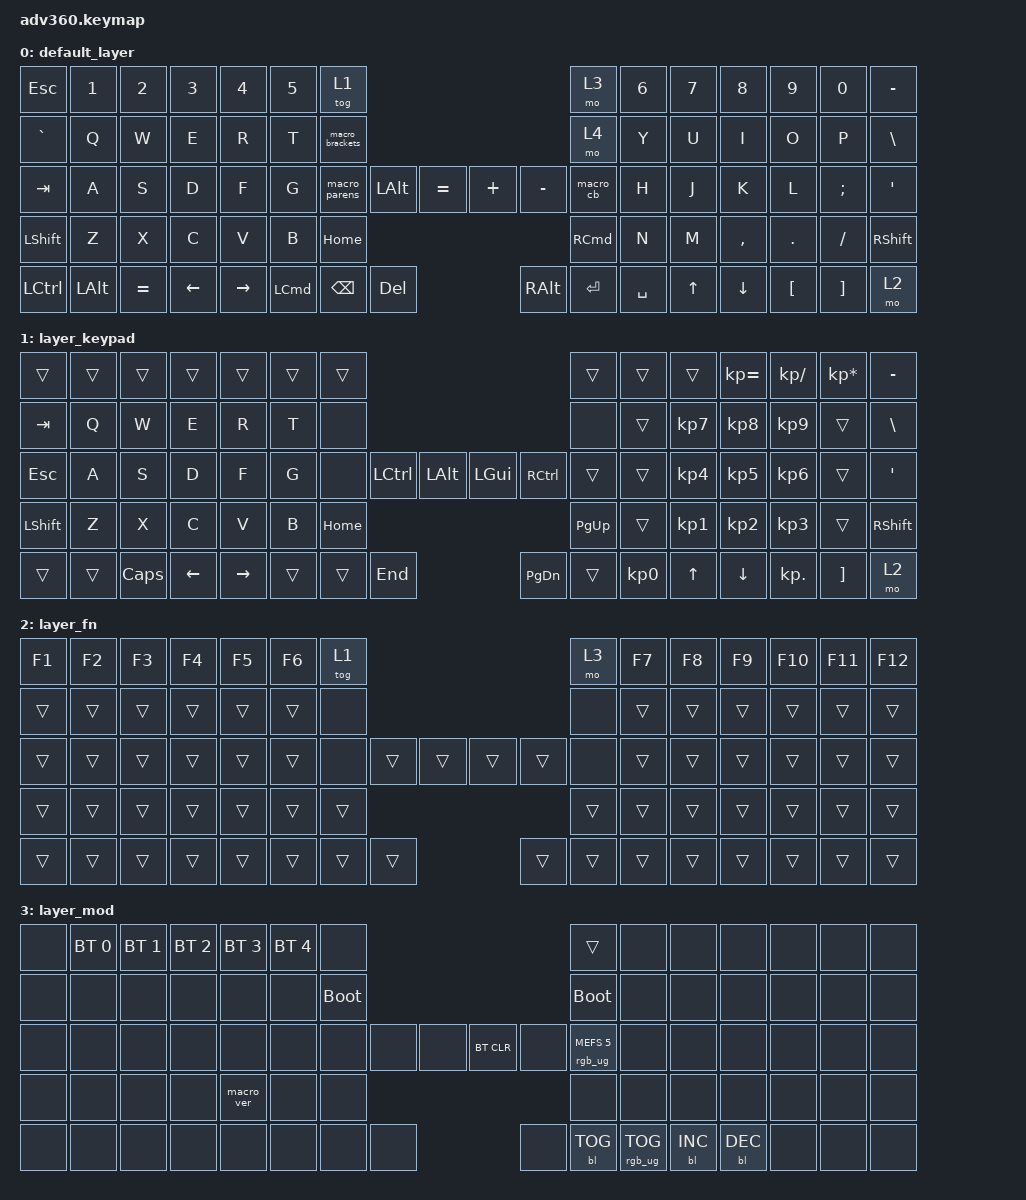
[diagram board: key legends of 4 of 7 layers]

/*
 * Copyright (c) 2020 The ZMK Contributors
 *
 * SPDX-License-Identifier: MIT
 */


/* THIS FILE WAS GENERATED!
 *
 * This file was generated automatically. You may or may not want to
 * edit it directly.
 */

#include <behaviors.dtsi>
#include <dt-bindings/zmk/keys.h>
#include <dt-bindings/zmk/bt.h>
#include <dt-bindings/zmk/rgb.h>
#include <dt-bindings/zmk/backlight.h>
#include "adv360keys.h"

#define COMBO(NAME, BINDINGS, KEYPOS) \
  combo_##NAME { \
    timeout-ms = <20>; \
    bindings = <BINDINGS>; \
    key-positions = <KEYPOS>; \
    layers = <0>; \
  };

&sk {
  release-after-ms = <STICKY_KEY_TIMEOUT>;
};

#define HYP(key) LS(LC(LA(LG(key))))
#define HYPER    LS(LC(LA(LGUI)))

#define MACLOCK  LG(LC(Q))

#define BROWSER_SEARCH LG(F)
#define BROWSER_NEWTAB LG(T)
#define BROWSER_CLOSETTAB LG(W)
#define BROWSER_NEXTTAB LG(LA(RIGHT))
#define BROWSER_PREVTAB LG(LA(LEFT))

&mt {
    tapping-term-ms = <210>;
    flavor = "tap-preferred";
};

&lt {
    quick_tap_ms = <200>;
};

/ {
    behaviors {
      #include "macros.dtsi"
      #include "version.dtsi"
      #ifndef VERSION_MACRO
      macro_ver: macro_ver {
        compatible = "zmk,behavior-macro";
        label = "macro_version";
        #binding-cells = <0>;
        bindings = <&kp RET>;
      };
      #endif
    combos {
      compatible = "zmk,combos";
      /* Brackets */
      COMBO(left_bracket, &kp LBKT, 0 10)
      COMBO(right_bracket, &kp RBKT, 7 17)
      COMBO(left_parenthesis, &kp LPAR, 1 11)
      COMBO(right_parenthesis, &kp RPAR, 6 16)
      COMBO(left_brace, &kp LBRC, 2 12)
      COMBO(right_brace, &kp RBRC, 5 15)
      /* Text */
      COMBO(redo, &kp LG(LS(Z)), 2 3)
      COMBO(undo, &kp LG(Z), 12 13)
      COMBO(redow, &kp LC(Y), 2 3)
      COMBO(undow, &kp LC(Z), 12 13)
      COMBO(caps_word, &caps_word, 31 32)
      COMBO(key_repeat_l, &key_repeat, 23 24)
      COMBO(key_repeat_r, &key_repeat, 25 26)
      COMBO(alfred, &kp LG(SPACE), 21 23)
      COMBO(clpbrd, &kp LG(LC(LA(LS(Z)))), 21 22 23)
      COMBO(esc, &kp ESC, 23 30)
    };

    // Sticky key on tap, normal key on hold
    // Useful for modifier-clicking without the modifier remaining active
    nk: not_so_sticky_key {
      compatible = "zmk,behavior-hold-tap";
      label = "NOT_SO_STICKY_KEY";
      #binding-cells = <2>;
      tapping_term_ms = <200>;
      flavor = "tap-preferred";
      bindings = <&kp>, <&sk>;
    };

    hm: homerow_mods {
        compatible = "zmk,behavior-hold-tap";
        label = "HOMEROW_MODS";
        #binding-cells = <2>;
        tapping-term-ms = <200>;
        quick_tap_ms = <175>;
        flavor = "tap-preferred";
        bindings = <&kp>, <&kp>;
    };
    gpipe: grave_pipe {
      compatible = "zmk,behavior-mod-morph";
      label = "grave_pipe";
      #binding-cells = <0>;
      bindings = <&kp GRAVE>, <&kp PIPE>;
      mods = <(MOD_LGUI|MOD_LSFT|MOD_RGUI|MOD_RSFT)>;
    };
  ppipe: pipe_pipe {
    compatible = "zmk,behavior-mod-morph";
    label = "pipe_pipe";
    #binding-cells = <0>;
    bindings = <&kp PIPE>, <&kp PIPE>;
    mods = <(MOD_LGUI|MOD_LSFT|MOD_RGUI|MOD_RSFT)>;
  };
  pkp_n1: plus_kp_n1 {
    compatible = "zmk,behavior-mod-morph";
    label = "plus_kp_n1";
    #binding-cells = <0>;
    bindings = <&kp PLUS>, <&kp KP_N1>;
    mods = <(MOD_LGUI|MOD_LSFT|MOD_RGUI|MOD_RSFT)>;
  };
  lkp_n2: left_bracket_kp_n2 {
    compatible = "zmk,behavior-mod-morph";
    label = "left_bracket_kp_n2";
    #binding-cells = <0>;
    bindings = <&kp LEFT_BRACKET>, <&kp KP_N2>;
    mods = <(MOD_LGUI|MOD_LSFT|MOD_RGUI|MOD_RSFT)>;
  };
  lkp_n3: left_brace_kp_n3 {
    compatible = "zmk,behavior-mod-morph";
    label = "left_brace_kp_n3";
    #binding-cells = <0>;
    bindings = <&kp LEFT_BRACE>, <&kp KP_N3>;
    mods = <(MOD_LGUI|MOD_LSFT|MOD_RGUI|MOD_RSFT)>;
  };
  lkp_n4: left_parenthesis_kp_n4 {
    compatible = "zmk,behavior-mod-morph";
    label = "left_parenthesis_kp_n4";
    #binding-cells = <0>;
    bindings = <&kp LEFT_PARENTHESIS>, <&kp KP_N4>;
    mods = <(MOD_LGUI|MOD_LSFT|MOD_RGUI|MOD_RSFT)>;
  };
  akp_n5: amps_kp_n5 {
    compatible = "zmk,behavior-mod-morph";
    label = "amps_kp_n5";
    #binding-cells = <0>;
    bindings = <&kp AMPS>, <&kp KP_N5>;
    mods = <(MOD_LGUI|MOD_LSFT|MOD_RGUI|MOD_RSFT)>;
  };
  ekp_n6: equal_kp_n6 {
    compatible = "zmk,behavior-mod-morph";
    label = "equal_kp_n6";
    #binding-cells = <0>;
    bindings = <&kp EQUAL>, <&kp KP_N6>;
    mods = <(MOD_LGUI|MOD_LSFT|MOD_RGUI|MOD_RSFT)>;
  };
  eekp_n6: kp_n6_equal {
    compatible = "zmk,behavior-mod-morph";
    label = "kp_n6_equal";
    #binding-cells = <0>;
    bindings = <&kp KP_N6>,  <&kp EQUAL>;
    mods = <(MOD_LGUI|MOD_LSFT|MOD_RGUI|MOD_RSFT)>;
  };

  rkp_n7: right_parenthesis_kp_n7 {
    compatible = "zmk,behavior-mod-morph";
    label = "right_parenthesis_kp_n7";
    #binding-cells = <0>;
    bindings = <&kp RIGHT_PARENTHESIS>, <&kp KP_N7>;
    mods = <(MOD_LGUI|MOD_LSFT|MOD_RGUI|MOD_RSFT)>;
  };
  rkp_n8: right_brace_kp_n8 {
    compatible = "zmk,behavior-mod-morph";
    label = "right_brace_kp_n8";
    #binding-cells = <0>;
    bindings = <&kp RIGHT_BRACE>, <&kp KP_N8>;
    mods = <(MOD_LGUI|MOD_LSFT|MOD_RGUI|MOD_RSFT)>;
  };
  rkp_n9: right_bracket_kp_n9 {
    compatible = "zmk,behavior-mod-morph";
    label = "right_bracket_kp_n9";
    #binding-cells = <0>;
    bindings = <&kp RIGHT_BRACKET>, <&kp KP_N9>;
    mods = <(MOD_LGUI|MOD_LSFT|MOD_RGUI|MOD_RSFT)>;
};
  skp_n0: star_kp_n0 {
    compatible = "zmk,behavior-mod-morph";
    label = "star_kp_n0";
    #binding-cells = <0>;
    bindings = <&kp STAR>, <&kp KP_N0>;
    mods = <(MOD_LGUI|MOD_LSFT|MOD_RGUI|MOD_RSFT)>;
  };
  eprcnt: excl_prcnt {
    compatible = "zmk,behavior-mod-morph";
    label = "excl_prcnt";
    #binding-cells = <0>;
    bindings = <&kp EXCL>, <&kp PRCNT>;
    mods = <(MOD_LGUI|MOD_LSFT|MOD_RGUI|MOD_RSFT)>;
  };

  dgrave: dllr_grave {
    compatible = "zmk,behavior-mod-morph";
    label = "dllr_grave";
    #binding-cells = <0>;
    bindings = <&kp DLLR>, <&kp GRAVE>;
    mods = <(MOD_LGUI|MOD_LSFT|MOD_RGUI|MOD_RSFT)>;
  };
  ggrave: grave_grave {
    compatible = "zmk,behavior-mod-morph";
    label = "grave_grave";
    #binding-cells = <0>;
    bindings = <&kp GRAVE>, <&kp GRAVE>;
    mods = <(MOD_LGUI|MOD_LSFT|MOD_RGUI|MOD_RSFT)>;
  };
  bhash: bslh_hash {
    compatible = "zmk,behavior-mod-morph";
    label = "bslh_hash";
    #binding-cells = <0>;
    bindings = <&kp BSLH>, <&kp HASH>;
    mods = <(MOD_LGUI|MOD_LSFT|MOD_RGUI|MOD_RSFT)>;
  };
  acaret: at_caret {
    compatible = "zmk,behavior-mod-morph";
    label = "at_caret";
    #binding-cells = <0>;
    bindings = <&kp AT>, <&kp CARET>;
    mods = <(MOD_LGUI|MOD_LSFT|MOD_RGUI|MOD_RSFT)>;
  };
};

keymap {
  compatible = "zmk,keymap";

/* Note that default_layer is 0, layer_keypad is 1, layer_fn is 2 */
    default_layer {
      bindings = <
        &kp ESC   &kp N1    &kp N2   &kp N3   &kp N4     &kp N5 &tog 1                                                           &mo 3     &kp N6 &kp N7 &kp N8    &kp N9   &kp N0   &kp MINUS
        &kp GRAVE &kp Q     &kp W    &kp E    &kp R      &kp T  &macro_brackets                                                  &mo 4     &kp Y  &kp U  &kp I     &kp O    &kp P    &kp BSLH
        &kp TAB   &kp A     &kp S    &kp D    &kp F      &kp G  &macro_parens   &kp LALT &kp EQUAL &kp PLUS  &kp MINUS           &macro_cb &kp H  &kp J  &kp K     &kp L    &kp SEMI &kp SQT
        &kp LSHFT &kp Z     &kp X    &kp C    &kp V      &kp B                            &kp HOME &kp RCMD                                &kp N  &kp M  &kp COMMA &kp DOT  &kp FSLH &kp RSHFT
        &kp LCTRL &kp LALT &kp EQUAL &kp LEFT &kp RIGHT                &kp LCMD &kp BSPC  &kp DEL  &kp RALT  &kp ENTER &kp SPACE                  &kp UP &kp DOWN  &kp LBKT &kp RBKT &mo 2
      >;
    };

    /* LAYER 1 */
    layer_keypad {
      bindings = <
        &trans   &trans    &trans   &trans   &trans     &trans  &trans                                                           &trans &trans &trans  &kp KP_EQUAL &kp KP_DIVIDE &kp KP_MULTIPLY &kp MINUS
        &kp TAB   &kp Q     &kp W    &kp E    &kp R      &kp T  &none                                                            &none &trans  &kp KP_N7  &kp KP_N8    &kp KP_N9     &trans    &kp BSLH
        &kp ESC   &kp A     &kp S    &kp D    &kp F      &kp G  &none           &kp LCTRL &kp LALT &kp LGUI  &kp RCTRL           &trans &trans  &kp KP_N4  &kp KP_N5    &kp KP_N6     &trans     &kp SQT
        &kp LSHFT &kp Z     &kp X    &kp C    &kp V      &kp B                            &kp HOME &kp PG_UP                           &trans  &kp KP_N1  &kp KP_N2    &kp KP_N3     &trans    &kp RSHFT
        &trans    &trans &kp CAPSLOCK &kp LEFT &kp RIGHT                &trans &trans   &kp END  &kp PG_DN &trans &kp KP_N0          &kp UP     &kp DOWN     &kp KP_DOT    &kp RBKT        &mo 2
      >;
    };

    /* LAYER 2 */
    layer_fn {
      bindings = <
        &kp F1 &kp F2 &kp F3 &kp F4 &kp F5 &kp F6 &tog 1                                           &mo 3 &kp F7 &kp F8 &kp F9 &kp F10 &kp F11 &kp F12
        &trans &trans &trans &trans &trans &trans  &none                                           &none &trans &trans &trans &trans  &trans  &trans
        &trans &trans &trans &trans &trans &trans  &none        &trans &trans &trans &trans        &none &trans &trans &trans &trans  &trans  &trans
        &trans &trans &trans &trans &trans &trans                      &trans &trans                     &trans &trans &trans &trans  &trans  &trans
        &trans &trans &trans &trans &trans               &trans &trans &trans &trans &trans &trans              &trans &trans &trans  &trans  &trans
      >;
    };

    /* LAYER 3 - for bootloading, etc */
    layer_mod {
      bindings = <
        &none &bt BT_SEL 0 &bt BT_SEL 1 &bt BT_SEL 2 &bt BT_SEL 3 &bt BT_SEL 4 &none                                                                     &trans                 &none        &none        &none        &none &none &none
        &none &none        &none        &none        &none        &none        &bootloader                                                               &bootloader            &none        &none        &none        &none &none &none
        &none &none        &none        &none        &none        &none        &none                   &none &none &bt BT_CLR &none                      &rgb_ug RGB_MEFS_CMD 5 &none        &none        &none        &none &none &none
        &none &none        &none        &none        &macro_ver   &none                                      &none &none                                                        &none        &none        &none        &none &none &none
        &none &none        &none        &none        &none                                       &none &none &none &none      &bl BL_TOG &rgb_ug RGB_TOG                                     &bl BL_INC   &bl BL_DEC   &none &none &none
      >;
    };

    /* LAYER 4 */
    prime_layer {
      bindings = <
        &ppipe    &pkp_n1     &lkp_n2   &lkp_n3  &lkp_n4    &akp_n5      &tog 4                                                                                                 &mo 3             &ekp_n6  &rkp_n7  &rkp_n8   &rkp_n9   &skp_n0  &eprcnt
        &kp TAB   &kp SEMI    &kp COMMA &kp DOT  &kp P      &kp Y        &none                                                                                                  &macro_kinesis    &kp F    &kp G    &kp C     &kp R     &kp L    &bhash
        &kp ESC   &kp A       &kp O     &kp E    &kp U      &kp I        &none                    &kp LCTRL    &kp LALT  &kp LGUI  &none       &kp RCTRL    &none               &none             &kp D    &kp H    &kp T     &kp N     &kp S    &kp MINUS
        &kp LSHFT &kp APOS    &kp Q     &kp J    &kp K      &kp X                 &none           &none        &kp HOME  &none     &none       &kp PG_UP    &none        &none                    &kp B    &kp M    &kp W     &kp V     &kp Z    &kp RSHFT
        &mo 2     &dgrave     &ggrave   &kp LEFT &kp RIGHT                        &kp BKSP        &kp LSHFT    &kp END                         &kp PG_DN    &kp ENTER    &kp SPACE                         &kp UP   &kp DOWN  &kp FSLH  &acaret  &mo 2
      >;
    };

    // https://github.com/fatih/Adv360-Pro-ZMK/blob/V2.0/config/adv360.keymap
    /* LAYER 5 */
    fatih_layer {
      bindings = <
        &kp EQUAL     &kp N1  &kp N2  &kp N3 &kp N4   &kp N5     &tog 4                                                                                                            &mo 3         &kp N6       &kp N7     &kp N8      &kp N9      &kp N0   &kp MINUS
        &kp TAB       &kp Q   &kp W   &kp E  &kp R    &kp T      &none                                                                                                             &tog 5        &kp Y        &kp U      &kp I       &kp O       &kp P    &kp BSLH
        &kp LCTRL     &kp A   &kp S   &kp D  &lt 1 F  &kp G      &none                    &kp HYP(N7)  &kp HYP(N8)  &none      &none         &kp RALT     &kp ESC                  &kp MACLOCK   &kp H        &kp J      &kp K       &kp L       &kp SEMI &mt RCTRL SQT
        &kp LSHFT     &kp Z   &kp X   &kp C  &kp V    &kp B                 &none         &none        &kp HYPER    &none      &none         &kp PG_UP    &none      &none                       &kp N        &kp M      &kp COMMA   &kp DOT     &kp FSLH &kp RSHFT
        &kp TAB       &kp GRAVE  &kp CAPSLOCK  &kp LEFT  &kp RIGHT          &kp LGUI      &kp BSPC     &kp HYP(N5)                           &kp PG_DN    &kp ENTER  &lt 2 SPACE                              &kp UP     &kp DOWN    &kp LBKT    &kp RBKT &mo 2
     >;
    };

    /* LAYER 6 - not sure what this does tbh */
    default_layer2 {
      bindings = <
        &kp ESC        &pkp_n1   &lkp_n2   &lkp_n3    &lkp_n4 &akp_n5    &tog 4                                                                                             &mo 3               &ekp_n6 &rkp_n7    &rkp_n8     &rkp_n9   &skp_n0      &kp MINUS
        &kp GRAVE      &kp Q     &kp W     &kp E      &kp R   &kp T      &macro_brackets                                                                                    &tog 5              &kp Y   &kp U      &kp I       &kp O     &kp P        &bhash
        &kp TAB        &kp A     &kp S     &kp D      &kp F   &kp G      &macro_parens               &macro_dquotes  &kp LALT   &none   &none  &kp RCTRL  &kp RCMD          &kp LA(BACKSPACE)   &kp H   &kp J      &kp K       &kp L     &kp SEMI     &kp SQT
        &kp LSHFT      &kp Z     &kp X     &kp C      &kp V   &kp B                    &none         &none           &kp HYPER  &none   &none  &kp PG_UP  &none      &none                      &kp N   &kp M      &kp COMMA   &kp DOT   &kp FSLH     &kp RSHFT
        &mo 2          &dgrave &ggrave     &kp LEFT   &kp RIGHT                        &kp LCMD      &kp BSPC        &kp ESC                   &kp PG_DN  &kp ENTER  &kp SPACE                          &kp UP     &kp DOWN    &kp CAPSLOCK  &acaret  &mo 2
      >;
    };
  };
};
